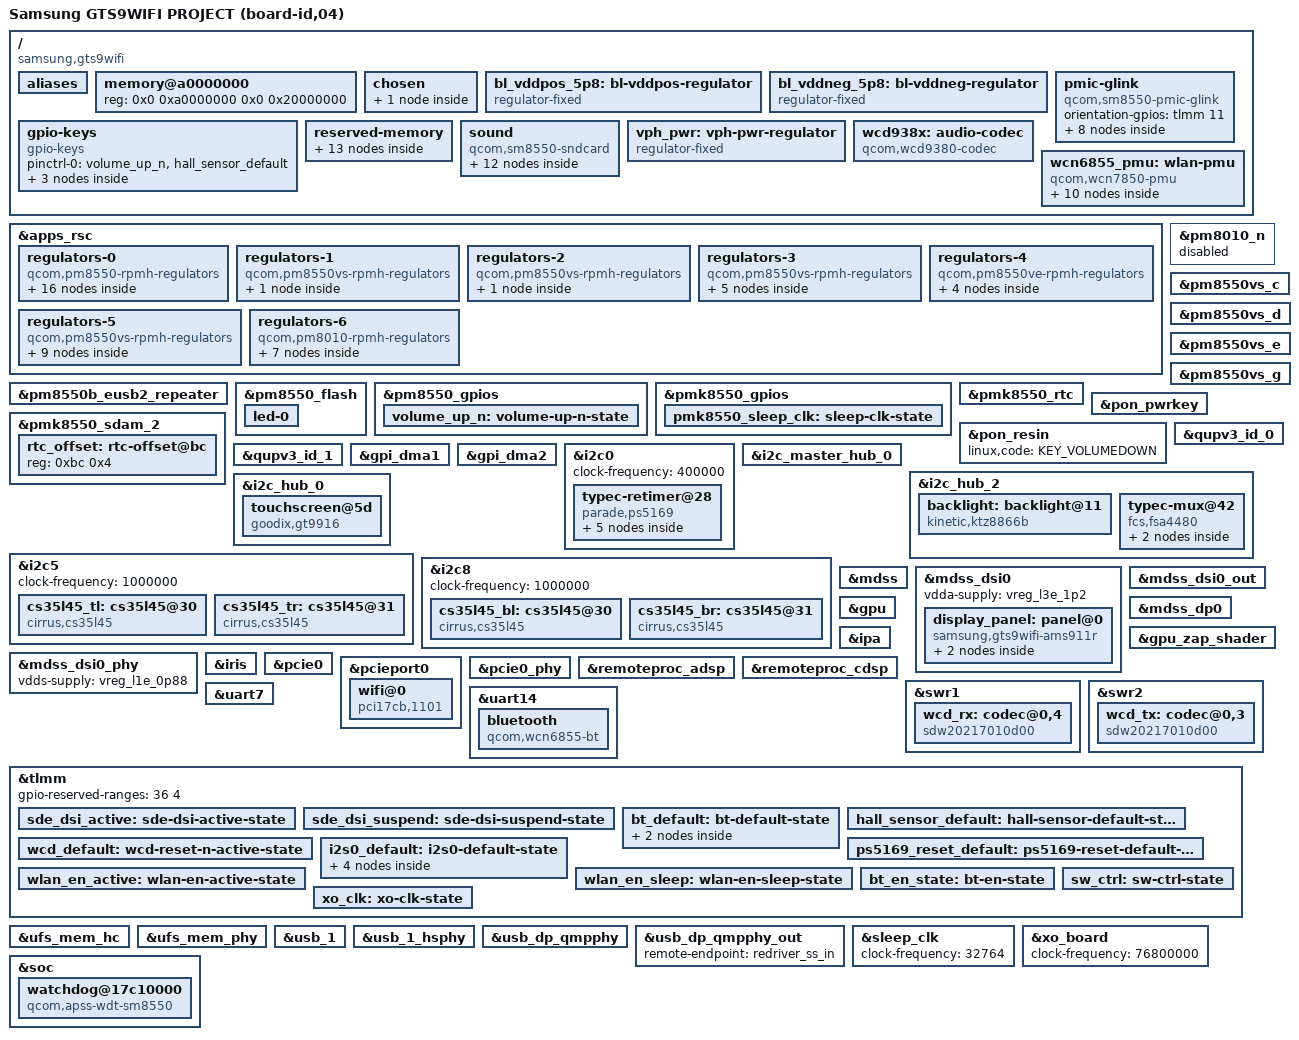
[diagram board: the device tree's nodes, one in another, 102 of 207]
// SPDX-License-Identifier: BSD-3-Clause
/*
 * Copyright (c) 2026, Azkali Manad <a.ffcc7@gmail.com>
 *
 * Device tree for Samsung Galaxy Tab S9 Wi-Fi (SM-X710)
 * Codename: gts9wifi — Qualcomm SM8550 (Snapdragon 8 Gen 2)
 *
 */

/dts-v1/;

#include <dt-bindings/arm/qcom,ids.h>
#include <dt-bindings/leds/common.h>
#include <dt-bindings/pinctrl/qcom,pmic-gpio.h>
#include <dt-bindings/regulator/qcom,rpmh-regulator.h>
#include "sm8550.dtsi"
#include "pm8010.dtsi"
#include "pm8550.dtsi"
#include "pm8550b.dtsi"
/* PMK8550VE shares SID 5 — must precede pm8550ve.dtsi */
#define PMK8550VE_SID 5
#include "pm8550ve.dtsi"
#include "pm8550vs.dtsi"
#include "pmk8550.dtsi"

/delete-node/ &xbl_dt_log_merged_mem;
/delete-node/ &hwfence_shbuf;
/delete-node/ &hyp_tags_reserved_mem;
/delete-node/ &cdsp_secure_heap_mem;
/delete-node/ &trust_ui_vm_mem;
/delete-node/ &trust_ui_vm_dump;
/delete-node/ &trust_ui_vm_qrtr;
/delete-node/ &trust_ui_vm_vblk0_ring;
/delete-node/ &trust_ui_vm_vblk1_ring;
/delete-node/ &trust_ui_vm_swiotlb;
/delete-node/ &oem_vm_vblk0_ring;
/delete-node/ &oem_vm_swiotlb;
/delete-node/ &oem_vm_mem;
/delete-node/ &hyp_ext_tags_mem;
/delete-node/ &hyp_ext_reserved_mem;
/delete-node/ &mpss_dsm_mem;
/delete-node/ &mpss_mem;
/delete-node/ &q6_mpss_dtb_mem;
/delete-node/ &remoteproc_mpss;
/delete-node/ &adspslpi_mem;
/delete-node/ &rmtfs_mem;

/ {
	model = "Samsung GTS9WIFI PROJECT (board-id,04)";
	compatible = "samsung,gts9wifi", "qcom,sm8550", "qcom,kalama-mtp", "qcom,kalama", "qcom,mtp";
	chassis-type = "tablet";
        qcom,msm-id = <0x218 0x20000 0x207 0x20000 0x207 0x10000 0x218 0x10000>;
	qcom,board-id = <0x10008 0x04>;
        dtbo-hw_rev = <0x04>;
        dtbo-hw_rev_end = <0x20>;


	aliases {
		serial0 = &uart7;   /* debug UART (QUP SE7)  */
		serial1 = &uart14;  /* Bluetooth (QUP SE14)  */
	};

	/*
	 * Embedded-DTB path: ABL doesn't patch our blob, so describe a
	 * conservative 512 MiB slice of DRAM at 0xa0000000–0xc0000000.
	 * /proc/iomem on stock confirms System RAM here (excluding splash
	 * region 0xb8000000–0xbab00000 which we mark no-map).
	 */
	memory@a0000000 {
		device_type = "memory";
		reg = <0x0 0xa0000000 0x0 0x20000000>;
	};

	chosen {
		#address-cells = <2>;
		#size-cells = <2>;
		ranges;

		stdout-path = "serial0:115200n8";
		bootargs = "earlycon=qcom_geni,0xa9c000,115200 console=ttyMSM0,115200 loglevel=8 clk_ignore_unused pd_ignore_unused udmabuf.size_limit_mb=256";

		framebuffer: framebuffer@b8000000 {
			compatible = "simple-framebuffer";
			reg = <0x0 0xb8000000 0x0 (1600 * 2560 * 4)>;
			width = <1600>;
			height = <2560>;
			stride = <(1600 * 4)>;
			format = "a8r8g8b8";
		};
	};

	bl_vddpos_5p8: bl-vddpos-regulator {
		compatible = "regulator-fixed";
		regulator-name = "bl_vddpos_5p8";
		regulator-min-microvolt = <5800000>;
		regulator-max-microvolt = <5800000>;
		regulator-enable-ramp-delay = <233>;
		gpio = <&tlmm 30 GPIO_ACTIVE_HIGH>;
		enable-active-high;
	};

	bl_vddneg_5p8: bl-vddneg-regulator {
		compatible = "regulator-fixed";
		regulator-name = "bl_vddneg_5p8";
		regulator-min-microvolt = <5800000>;
		regulator-max-microvolt = <5800000>;
		regulator-enable-ramp-delay = <233>;
		gpio = <&tlmm 31 GPIO_ACTIVE_HIGH>;
		enable-active-high;
	};

	gpio-keys {
		compatible = "gpio-keys";
		pinctrl-0 = <&volume_up_n>, <&hall_sensor_default>;
		pinctrl-names = "default";

		key-volume-up {
			label = "Volume Up";
			linux,code = <KEY_VOLUMEUP>;
			gpios = <&pm8550_gpios 6 GPIO_ACTIVE_LOW>;
			debounce-interval = <15>;
			linux,can-disable;
			wakeup-source;
		};

		event-hall-sensor {
			label = "Hall Effect Sensor";
			gpios = <&tlmm 107 GPIO_ACTIVE_LOW>;
			linux,input-type = <EV_SW>;
			linux,code = <SW_LID>;
			debounce-interval = <15>;
			linux,can-disable;
			wakeup-source;
		};

		event-hall-wacom {
			label = "Hall Effect Sensor (Wacom S-Pen)";
			gpios = <&tlmm 203 GPIO_ACTIVE_LOW>;
			linux,input-type = <EV_SW>;
			linux,code = <SW_TABLET_MODE>;
			debounce-interval = <15>;
			linux,can-disable;
		};
	};

	pmic-glink {
		compatible = "qcom,sm8550-pmic-glink", "qcom,pmic-glink";
		#address-cells = <1>;
		#size-cells = <0>;
		orientation-gpios = <&tlmm 11 GPIO_ACTIVE_HIGH>;

		connector@0 {
			compatible = "usb-c-connector";
			reg = <0>;
			power-role = "dual";
			data-role = "dual";

			ports {
				#address-cells = <1>;
				#size-cells = <0>;

				port@0 {
					reg = <0>;
					pmic_glink_hs_in: endpoint {
						remote-endpoint = <&usb_1_dwc3_hs>;
					};
				};
				port@1 {
					reg = <1>;
					pmic_glink_ss_in: endpoint {
						remote-endpoint = <&redriver_ss_out>;
					};
				};
				port@2 {
					reg = <2>;
					pmic_glink_sbu: endpoint {
						remote-endpoint = <&fsa4480_sbu_mux>;
					};
				};
			};
		};
	};

	/*
	 * Reserved-memory carveouts derived from the stock gts9wifi
	 * bootloader (BL_X710XXU5CYD9 — xbl_config.elf "Kailua" memory
	 * map). Only regions the hardware still reads during the
	 * UEFI→Linux hand-off are kept no-map; ranges freed by
	 * ExitBootServices (DXE heap, UEFI FD) or migrated out by
	 * uniLoader stripping the Qualcomm hypervisor (trust_ui_vm,
	 * oem_vm, hyp_ext, RSRV3) are left available to Linux.
	 */
	reserved-memory {
		xbl_ramdump_mem: xbl-ramdump-region@81200000 {
			reg = <0 0x81200000 0 0x280000>;
			no-map;
		};

		xbl_dt_log_mem: xbl-dt-log-region@81a00000 {
			reg = <0 0x81a00000 0 0x40000>;
			no-map;
		};

		aop_image_mem: aop-image-region@81c00000 {
			reg = <0 0x81c00000 0 0x60000>;
			no-map;
		};

		adspslpi_mem: adspslpi-region@9ea00000 {
			reg = <0 0x9ea00000 0 0x4080000>;
			no-map;
		};

		/*
		 * Samsung downstream DPU programs a demura calibration LUT
		 * here at boot and the display controller keeps scanning it
		 * until the mainline msm DRM driver reinitialises the
		 * pipeline. Reserve it so simple-framebuffer hand-off can't
		 * clobber an in-flight DPU read.
		 */
		display_demura_mem: display-demura-region@a2a80000 {
			reg = <0x0 0xa2a80000 0x0 0x2b00000>;
			no-map;
		};

		/* XBL "RSRV2" — purpose undocumented, reserved out of caution. */
		rsrv2_mem: rsrv2-region@a5580000 {
			reg = <0x0 0xa5580000 0x0 0xb80000>;
			no-map;
		};

		/*
		 * XBL "DBI Dump" — debug boot-info dump target, mapped as
		 * MMAP_IO in the bootloader memory map but still falls
		 * inside the DDR window Linux enumerates.
		 */
		dbi_dump_mem: dbi-dump-region@a6100000 {
			reg = <0x0 0xa6100000 0x0 0xf00000>;
			no-map;
		};

		/*
		 * Bootloader's "Display Reserved" is 43 MiB, covering the
		 * 1600x2560x4 framebuffer plus Samsung secondary / cursor
		 * planes. simple-framebuffer only uses the first ~16 MiB
		 * but the whole region must stay no-map until takeover.
		 */
		cont_splash_mem: splash-region@b8000000 {
			reg = <0x0 0xb8000000 0x0 0x2b00000>;
			no-map;
		};

		rmtfs_mem: rmtfs-region@ccd00000 {
			compatible = "qcom,rmtfs-mem";
			reg = <0x0 0xccd00000 0x0 0x280000>;
			no-map;
			qcom,client-id = <1>;
		};

		hwfence_shbuf: hwfence-shbuf-region@e6440000 {
			reg = <0 0xe6440000 0 0x2dd000>;
			no-map;
		};

		ramoops@f0000000 {
			compatible = "ramoops";
			reg = <0x0 0xf0000000 0x0 0x200000>;
			record-size  = <0x40000>;	/* 256 KiB per oops record  */
			console-size = <0x80000>;	/* 512 KiB kernel console   */
			pmsg-size    = <0x40000>;	/* 256 KiB userspace pmsg   */
			/* remaining ~768 KiB is padding / alignment slack   */
			mem-type = <0>;
			no-map;
		};

		/* XBL "NOMAP" carveout at top of low bank, 8 MiB. */
		llcc_lpi_mem: llcc-lpi-region@ff800000 {
			reg = <0 0xff800000 0 0x800000>;
			no-map;
		};

		linux,cma {
			compatible = "shared-dma-pool";
			size = <0x0 0x20000000>;	/* 512 MiB */
			reusable;
			linux,cma-default;
		};
	};

	sound {
		compatible = "qcom,sm8550-sndcard", "qcom,sm8450-sndcard";
		model = "Samsung-GTS9WiFi";
		pinctrl-names = "default";
		pinctrl-0 = <&i2s0_default>;

		audio-routing =
			"IN1_HPHL",      "HPHL_OUT",
			"IN2_HPHR",      "HPHR_OUT",
			"AMIC1",         "MIC BIAS1",
			"AMIC2",         "MIC BIAS2",
			"AMIC3",         "MIC BIAS3",
			"AMIC4",         "MIC BIAS3",
			"TX SWR_INPUT0", "ADC1_OUTPUT",
			"TX SWR_INPUT1", "ADC2_OUTPUT",
			"TX SWR_INPUT0", "ADC3_OUTPUT",
			"TX SWR_INPUT1", "ADC4_OUTPUT";

		speaker-dai-link {
			link-name = "CS35L41 Speaker Playback";
			cpu    { sound-dai = <&q6apmbedai SECONDARY_MI2S_RX>; };
			codec  { sound-dai = <&cs35l45_tl>, <&cs35l45_tr>,
					     <&cs35l45_bl>, <&cs35l45_br>; };
			platform { sound-dai = <&q6apm>; };
		};

		wcd-playback-dai-link {
			link-name = "WCD Playback";
			cpu    { sound-dai = <&q6apmbedai RX_CODEC_DMA_RX_0>; };
			codec  { sound-dai = <&wcd938x 0>, <&swr1 0>, <&lpass_rxmacro 0>; };
			platform { sound-dai = <&q6apm>; };
		};

		wcd-capture-dai-link {
			link-name = "WCD Capture";
			cpu    { sound-dai = <&q6apmbedai TX_CODEC_DMA_TX_3>; };
			codec  { sound-dai = <&wcd938x 1>, <&swr2 0>, <&lpass_txmacro 0>; };
			platform { sound-dai = <&q6apm>; };
		};
	};

	vph_pwr: vph-pwr-regulator {
		compatible = "regulator-fixed";
		regulator-name = "vph_pwr";
		regulator-min-microvolt = <3700000>;
		regulator-max-microvolt = <3700000>;
		regulator-always-on;
		regulator-boot-on;
	};

	wcd938x: audio-codec {
		compatible = "qcom,wcd9380-codec";
		pinctrl-names = "default";
		pinctrl-0 = <&wcd_default>;

		qcom,micbias1-microvolt = <2750000>;
		qcom,micbias2-microvolt = <2750000>;
		qcom,micbias3-microvolt = <2750000>;
		qcom,micbias4-microvolt = <2750000>;
		qcom,mbhc-buttons-vthreshold-microvolt =
			<75000 150000 237000 500000
			 500000 500000 500000 500000>;
		qcom,mbhc-headset-vthreshold-microvolt = <1700000>;
		qcom,mbhc-headphone-vthreshold-microvolt = <50000>;
		qcom,rx-device = <&wcd_rx>;
		qcom,tx-device = <&wcd_tx>;

		reset-gpios = <&tlmm 108 GPIO_ACTIVE_LOW>;

		vdd-buck-supply     = <&vreg_l15b_1p8>;
		vdd-rxtx-supply     = <&vreg_l15b_1p8>;
		vdd-io-supply       = <&vreg_l15b_1p8>;
		vdd-mic-bias-supply = <&vreg_bob1>;

		#sound-dai-cells = <1>;
	};

	wcn6855_pmu: wlan-pmu {
		compatible = "qcom,wcn7850-pmu";

		pinctrl-names = "default", "sleep";
		pinctrl-0 = <&wlan_en_active>, <&bt_en_state>, <&xo_clk>;
		pinctrl-1 = <&wlan_en_sleep>;

		wlan-enable-gpios = <&tlmm 80 GPIO_ACTIVE_HIGH>;
		bt-enable-gpios   = <&tlmm 81 GPIO_ACTIVE_HIGH>;
		swctrl-gpios      = <&tlmm 82 GPIO_ACTIVE_HIGH>;
		xo-clk-gpios      = <&tlmm 204 GPIO_ACTIVE_HIGH>;

		vdd-supply        = <&vreg_s2g_0p8>;
		vddio-supply      = <&vreg_l15b_1p8>;
		vddaon-supply     = <&vreg_s2g_0p8>;
		vdddig-supply     = <&vreg_s4e_0p9>;
		vddrfa1p2-supply  = <&vreg_s4g_1p3>;
		vddrfa1p8-supply  = <&vreg_s6g_1p8>;
		vddpcie1p3-supply = <&vreg_s4g_1p3>;
		vddpcie1p9-supply = <&vreg_s6g_1p8>;
		vddpmu-supply     = <&vreg_s2g_0p8>;
		vddpmumx-supply   = <&vreg_s2g_0p8>;
		vddpmucx-supply   = <&vreg_s4e_0p9>;

		regulators {
			vreg_pmu_rfa_cmn:  ldo0 { regulator-name = "vreg_pmu_rfa_cmn"; };
			vreg_pmu_aon_0p59: ldo1 { regulator-name = "vreg_pmu_aon_0p59"; };
			vreg_pmu_wlcx_0p8: ldo2 { regulator-name = "vreg_pmu_wlcx_0p8"; };
			vreg_pmu_wlmx_0p85: ldo3 { regulator-name = "vreg_pmu_wlmx_0p85"; };
			vreg_pmu_rfa_0p8:  ldo5 { regulator-name = "vreg_pmu_rfa_0p8"; };
			vreg_pmu_rfa_1p2:  ldo6 { regulator-name = "vreg_pmu_rfa_1p2"; };
			vreg_pmu_rfa_1p8:  ldo7 { regulator-name = "vreg_pmu_rfa_1p8"; };
			vreg_pmu_pcie_0p9: ldo8 { regulator-name = "vreg_pmu_pcie_0p9"; };
			vreg_pmu_pcie_1p8: ldo9 { regulator-name = "vreg_pmu_pcie_1p8"; };
		};
	};
};

&apps_rsc {
	regulators-0 {
		compatible = "qcom,pm8550-rpmh-regulators";
		qcom,pmic-id = "b";

		vdd-bob1-supply       = <&vph_pwr>;
		vdd-bob2-supply       = <&vph_pwr>;
		vdd-l1-l4-l10-supply  = <&vreg_s6g_1p8>;
		vdd-l2-l13-l14-supply = <&vreg_bob1>;
		vdd-l3-supply         = <&vreg_s4g_1p3>;
		vdd-l5-l16-supply     = <&vreg_bob1>;
		vdd-l6-l7-supply      = <&vreg_bob1>;
		vdd-l8-l9-supply      = <&vreg_bob1>;
		vdd-l11-supply        = <&vreg_s4g_1p3>;
		vdd-l12-supply        = <&vreg_s6g_1p8>;
		vdd-l15-supply        = <&vreg_s6g_1p8>;
		vdd-l17-supply        = <&vreg_bob2>;

		vreg_bob1: bob1 {
			regulator-name = "vreg_bob1";
			regulator-min-microvolt = <3296000>;
			regulator-max-microvolt = <3960000>;
			regulator-initial-mode = <RPMH_REGULATOR_MODE_HPM>;
		};

		vreg_bob2: bob2 {
			regulator-name = "vreg_bob2";
			regulator-min-microvolt = <2720000>;
			regulator-max-microvolt = <3960000>;
			regulator-initial-mode = <RPMH_REGULATOR_MODE_HPM>;
		};

		vreg_l1b_1p8: ldo1 {
			regulator-name = "vreg_l1b_1p8";
			regulator-min-microvolt = <1800000>;
			regulator-max-microvolt = <1800000>;
			regulator-initial-mode = <RPMH_REGULATOR_MODE_HPM>;
		};

		vreg_l2b_3p0: ldo2 {
			regulator-name = "vreg_l2b_3p0";
			regulator-min-microvolt = <3008000>;
			regulator-max-microvolt = <3008000>;
			regulator-initial-mode = <RPMH_REGULATOR_MODE_HPM>;
		};

		vreg_l5b_3p1: ldo5 {
			regulator-name = "vreg_l5b_3p1";
			regulator-min-microvolt = <3104000>;
			regulator-max-microvolt = <3104000>;
			regulator-initial-mode = <RPMH_REGULATOR_MODE_HPM>;
		};

		vreg_l6b_1p8: ldo6 {
			regulator-name = "vreg_l6b_1p8";
			regulator-min-microvolt = <1800000>;
			regulator-max-microvolt = <3008000>;
			regulator-initial-mode = <RPMH_REGULATOR_MODE_HPM>;
		};

		vreg_l7b_1p8: ldo7 {
			regulator-name = "vreg_l7b_1p8";
			regulator-min-microvolt = <1800000>;
			regulator-max-microvolt = <3008000>;
			regulator-initial-mode = <RPMH_REGULATOR_MODE_HPM>;
		};

		vreg_l8b_1p8: ldo8 {
			regulator-name = "vreg_l8b_1p8";
			regulator-min-microvolt = <1800000>;
			regulator-max-microvolt = <3008000>;
			regulator-initial-mode = <RPMH_REGULATOR_MODE_HPM>;
		};

		vreg_l9b_2p9: ldo9 {
			regulator-name = "vreg_l9b_2p9";
			regulator-min-microvolt = <2960000>;
			regulator-max-microvolt = <3008000>;
			regulator-initial-mode = <RPMH_REGULATOR_MODE_HPM>;
		};

		vreg_l11b_1p2: ldo11 {
			regulator-name = "vreg_l11b_1p2";
			regulator-min-microvolt = <1200000>;
			regulator-max-microvolt = <1504000>;
			regulator-initial-mode = <RPMH_REGULATOR_MODE_HPM>;
		};

		vreg_l12b_1p8: ldo12 {
			regulator-name = "vreg_l12b_1p8";
			regulator-min-microvolt = <1800000>;
			regulator-max-microvolt = <1800000>;
			regulator-initial-mode = <RPMH_REGULATOR_MODE_HPM>;
		};

		vreg_l13b_3p0: ldo13 {
			regulator-name = "vreg_l13b_3p0";
			regulator-min-microvolt = <3000000>;
			regulator-max-microvolt = <3000000>;
			regulator-initial-mode = <RPMH_REGULATOR_MODE_HPM>;
		};

		vreg_l14b_3p2: ldo14 {
			regulator-name = "vreg_l14b_3p2";
			regulator-min-microvolt = <3200000>;
			regulator-max-microvolt = <3200000>;
			regulator-initial-mode = <RPMH_REGULATOR_MODE_HPM>;
		};

		vreg_l15b_1p8: ldo15 {
			regulator-name = "vreg_l15b_1p8";
			regulator-min-microvolt = <1800000>;
			regulator-max-microvolt = <1800000>;
			regulator-initial-mode = <RPMH_REGULATOR_MODE_HPM>;
			regulator-allow-set-load;
			regulator-allowed-modes =
				<RPMH_REGULATOR_MODE_LPM
				 RPMH_REGULATOR_MODE_HPM>;
			regulator-always-on;
		};

		vreg_l16b_2p8: ldo16 {
			regulator-name = "vreg_l16b_2p8";
			regulator-min-microvolt = <2800000>;
			regulator-max-microvolt = <2800000>;
			regulator-initial-mode = <RPMH_REGULATOR_MODE_HPM>;
		};

		vreg_l17b_2p5: ldo17 {
			regulator-name = "vreg_l17b_2p5";
			regulator-min-microvolt = <2504000>;
			regulator-max-microvolt = <2504000>;
			regulator-initial-mode = <RPMH_REGULATOR_MODE_HPM>;
		};
	};

	regulators-1 {
		compatible = "qcom,pm8550vs-rpmh-regulators";
		qcom,pmic-id = "c";
		vdd-l3-supply = <&vreg_s4e_0p9>;

		vreg_l3c_0p91: ldo3 {
			regulator-name = "vreg_l3c_0p9";
			regulator-min-microvolt = <880000>;
			regulator-max-microvolt = <912000>;
			regulator-initial-mode = <RPMH_REGULATOR_MODE_HPM>;
		};
	};

	regulators-2 {
		compatible = "qcom,pm8550vs-rpmh-regulators";
		qcom,pmic-id = "d";
		vdd-l1-supply = <&vreg_s4e_0p9>;

		vreg_l1d_0p88: ldo1 {
			regulator-name = "vreg_l1d_0p88";
			regulator-min-microvolt = <880000>;
			regulator-max-microvolt = <920000>;
			regulator-initial-mode = <RPMH_REGULATOR_MODE_HPM>;
		};
	};

	regulators-3 {
		compatible = "qcom,pm8550vs-rpmh-regulators";
		qcom,pmic-id = "e";
		vdd-l1-supply = <&vreg_s4e_0p9>;
		vdd-l2-supply = <&vreg_s4e_0p9>;
		vdd-l3-supply = <&vreg_s4g_1p3>;
		vdd-s4-supply = <&vph_pwr>;
		vdd-s5-supply = <&vph_pwr>;

		vreg_s4e_0p9: smps4 {
			regulator-name = "vreg_s4e_0p9";
			regulator-min-microvolt = <904000>;
			regulator-max-microvolt = <984000>;
			regulator-initial-mode = <RPMH_REGULATOR_MODE_HPM>;
		};

		vreg_s5e_1p1: smps5 {
			regulator-name = "vreg_s5e_1p1";
			regulator-min-microvolt = <1080000>;
			regulator-max-microvolt = <1120000>;
			regulator-initial-mode = <RPMH_REGULATOR_MODE_HPM>;
		};

		vreg_l1e_0p88: ldo1 {
			regulator-name = "vreg_l1e_0p88";
			regulator-min-microvolt = <880000>;
			regulator-max-microvolt = <880000>;
			regulator-initial-mode = <RPMH_REGULATOR_MODE_HPM>;
		};

		vreg_l2e_0p9: ldo2 {
			regulator-name = "vreg_l2e_0p9";
			regulator-min-microvolt = <904000>;
			regulator-max-microvolt = <970000>;
			regulator-initial-mode = <RPMH_REGULATOR_MODE_HPM>;
		};

		vreg_l3e_1p2: ldo3 {
			regulator-name = "vreg_l3e_1p2";
			regulator-min-microvolt = <1200000>;
			regulator-max-microvolt = <1200000>;
			regulator-initial-mode = <RPMH_REGULATOR_MODE_HPM>;
		};
	};

	regulators-4 {
		compatible = "qcom,pm8550ve-rpmh-regulators";
		qcom,pmic-id = "f";
		vdd-l1-supply = <&vreg_s4e_0p9>;
		vdd-l2-supply = <&vreg_s4e_0p9>;
		vdd-l3-supply = <&vreg_s4e_0p9>;
		vdd-s4-supply = <&vph_pwr>;

		vreg_s4f_0p5: smps4 {
			regulator-name = "vreg_s4f_0p5";
			regulator-min-microvolt = <500000>;
			regulator-max-microvolt = <700000>;
			regulator-initial-mode = <RPMH_REGULATOR_MODE_HPM>;
		};

		vreg_l1f_0p9: ldo1 {
			regulator-name = "vreg_l1f_0p9";
			regulator-min-microvolt = <912000>;
			regulator-max-microvolt = <912000>;
			regulator-initial-mode = <RPMH_REGULATOR_MODE_HPM>;
		};

		vreg_l2f_0p88: ldo2 {
			regulator-name = "vreg_l2f_0p88";
			regulator-min-microvolt = <880000>;
			regulator-max-microvolt = <912000>;
			regulator-initial-mode = <RPMH_REGULATOR_MODE_HPM>;
		};

		vreg_l3f_0p91: ldo3 {
			regulator-name = "vreg_l3f_0p91";
			regulator-min-microvolt = <880000>;
			regulator-max-microvolt = <912000>;
			regulator-initial-mode = <RPMH_REGULATOR_MODE_HPM>;
		};
	};

	regulators-5 {
		compatible = "qcom,pm8550vs-rpmh-regulators";
		qcom,pmic-id = "g";
		vdd-l1-supply = <&vreg_s4g_1p3>;
		vdd-l2-supply = <&vreg_s4g_1p3>;
		vdd-l3-supply = <&vreg_s4g_1p3>;
		vdd-s1-supply = <&vph_pwr>;
		vdd-s2-supply = <&vph_pwr>;
		vdd-s3-supply = <&vph_pwr>;
		vdd-s4-supply = <&vph_pwr>;
		vdd-s5-supply = <&vph_pwr>;
		vdd-s6-supply = <&vph_pwr>;

		vreg_s1g_1p2: smps1 {
			regulator-name = "vreg_s1g_1p2";
			regulator-min-microvolt = <1200000>;
			regulator-max-microvolt = <1300000>;
			regulator-initial-mode = <RPMH_REGULATOR_MODE_HPM>;
		};

		vreg_s2g_0p8: smps2 {
			regulator-name = "vreg_s2g_0p8";
			regulator-min-microvolt = <800000>;
			regulator-max-microvolt = <1000000>;
			regulator-initial-mode = <RPMH_REGULATOR_MODE_HPM>;
		};

		vreg_s3g_0p7: smps3 {
			regulator-name = "vreg_s3g_0p7";
			regulator-min-microvolt = <600000>;
			regulator-max-microvolt = <1900000>;
			regulator-initial-mode = <RPMH_REGULATOR_MODE_HPM>;
		};

		vreg_s4g_1p3: smps4 {
			regulator-name = "vreg_s4g_1p3";
			regulator-min-microvolt = <1256000>;
			regulator-max-microvolt = <1408000>;
			regulator-initial-mode = <RPMH_REGULATOR_MODE_HPM>;
		};

		vreg_s5g_0p8: smps5 {
			regulator-name = "vreg_s5g_0p8";
			regulator-min-microvolt = <500000>;
			regulator-max-microvolt = <1004000>;
			regulator-initial-mode = <RPMH_REGULATOR_MODE_HPM>;
		};

		vreg_s6g_1p8: smps6 {
			regulator-name = "vreg_s6g_1p8";
			regulator-min-microvolt = <1800000>;
			regulator-max-microvolt = <2000000>;
			regulator-initial-mode = <RPMH_REGULATOR_MODE_HPM>;
		};

		vreg_l1g_1p2: ldo1 {
			regulator-name = "vreg_l1g_1p2";
			regulator-min-microvolt = <1200000>;
			regulator-max-microvolt = <1200000>;
			regulator-initial-mode = <RPMH_REGULATOR_MODE_HPM>;
		};

		vreg_l2g_1p2: ldo2 {
			regulator-name = "vreg_l2g_1p2";
			regulator-min-microvolt = <1200000>;
			regulator-max-microvolt = <1200000>;
			regulator-initial-mode = <RPMH_REGULATOR_MODE_HPM>;
		};

		vreg_l3g_1p2: ldo3 {
			regulator-name = "vreg_l3g_1p2";
			regulator-min-microvolt = <1200000>;
			regulator-max-microvolt = <1200000>;
			regulator-initial-mode = <RPMH_REGULATOR_MODE_HPM>;
		};
	};

	regulators-6 {
		compatible = "qcom,pm8010-rpmh-regulators";
		qcom,pmic-id = "m";
		vdd-l1-l2-supply = <&vreg_s4g_1p3>;
		vdd-l3-l4-supply = <&vreg_bob2>;
		vdd-l5-supply    = <&vreg_s6g_1p8>;
		vdd-l6-supply    = <&vreg_bob2>;
		vdd-l7-supply    = <&vreg_bob2>;

		vreg_l1m_1p056: ldo1 {
			regulator-name = "vreg_l1m_1p056";
			regulator-min-microvolt = <1056000>;
			regulator-max-microvolt = <1056000>;
			regulator-initial-mode = <RPMH_REGULATOR_MODE_HPM>;
		};

		vreg_l2m_1p056: ldo2 {
			regulator-name = "vreg_l2m_1p056";
			regulator-min-microvolt = <1056000>;
			regulator-max-microvolt = <1056000>;
			regulator-initial-mode = <RPMH_REGULATOR_MODE_HPM>;
		};

		vreg_l3m_2p8: ldo3 {
			regulator-name = "vreg_l3m_2p8";
			regulator-min-microvolt = <2800000>;
			regulator-max-microvolt = <2800000>;
			regulator-initial-mode = <RPMH_REGULATOR_MODE_HPM>;
		};

		vreg_l4m_2p8: ldo4 {
			regulator-name = "vreg_l4m_2p8";
			regulator-min-microvolt = <2800000>;
			regulator-max-microvolt = <2800000>;
			regulator-initial-mode = <RPMH_REGULATOR_MODE_HPM>;
		};

		vreg_l5m_1p8: ldo5 {
			regulator-name = "vreg_l5m_1p8";
			regulator-min-microvolt = <1800000>;
			regulator-max-microvolt = <1800000>;
			regulator-initial-mode = <RPMH_REGULATOR_MODE_HPM>;
		};

		vreg_l6m_1p8: ldo6 {
			regulator-name = "vreg_l6m_1p8";
			regulator-min-microvolt = <1800000>;
			regulator-max-microvolt = <1800000>;
			regulator-initial-mode = <RPMH_REGULATOR_MODE_HPM>;
		};

		vreg_l7m_2p9: ldo7 {
			regulator-name = "vreg_l7m_2p9";
			regulator-min-microvolt = <2800000>;
			regulator-max-microvolt = <2904000>;
			regulator-initial-mode = <RPMH_REGULATOR_MODE_HPM>;
		};
	};
};

&pm8010_n { status = "disabled"; };

&pm8550b_eusb2_repeater {
	vdd18-supply = <&vreg_l15b_1p8>;
	vdd3-supply  = <&vreg_l5b_3p1>;
};

&pm8550_flash {
	status = "okay";
	led-0 {
		function = LED_FUNCTION_FLASH;
		color = <LED_COLOR_ID_WHITE>;
		led-sources = <1>;
		led-max-microamp = <400000>;
		flash-max-microamp = <400000>;
		flash-max-timeout-us = <300000>;
		function-enumerator = <0>;
	};
};

&pm8550_gpios {
	volume_up_n: volume-up-n-state {
		pins = "gpio6";
		function = "normal";
		power-source = <1>;
		bias-pull-up;
		input-enable;
	};
};

&pm8550vs_c { status = "okay"; };
&pm8550vs_d { status = "okay"; };
&pm8550vs_e { status = "okay"; };
&pm8550vs_g { status = "okay"; };

&pmk8550_gpios {
	pmk8550_sleep_clk: sleep-clk-state {
		pins = "gpio3";
		function = "func1";
		input-disable;
		output-enable;
		bias-disable;
		power-source = <0>;
	};
};

&pmk8550_rtc {
	nvmem-cells = <&rtc_offset>;
	nvmem-cell-names = "offset";
};

&pmk8550_sdam_2 {
	rtc_offset: rtc-offset@bc {
		reg = <0xbc 0x4>;
	};
};

&pon_pwrkey { status = "okay"; };
&pon_resin  { status = "okay"; linux,code = <KEY_VOLUMEDOWN>; };

&qupv3_id_0 { status = "okay"; };
&qupv3_id_1 { status = "okay"; };

&gpi_dma1 { status = "okay"; };
&gpi_dma2 { status = "okay"; };

&i2c0 {
	clock-frequency = <400000>;
	status = "okay";

	typec-retimer@28 {
		compatible = "parade,ps5169";
		reg = <0x28>;
		pinctrl-names = "default";
		pinctrl-0 = <&ps5169_reset_default>;
		reset-gpios = <&tlmm 7 GPIO_ACTIVE_LOW>;
		orientation-switch;
		retimer-switch;

		ports {
			#address-cells = <1>;
			#size-cells = <0>;
			port@0 {
				reg = <0>;
				redriver_ss_out: endpoint {
					remote-endpoint = <&pmic_glink_ss_in>;
				};
			};
			port@1 {
				reg = <1>;
				redriver_ss_in: endpoint {
					data-lanes = <3 2 1 0>;
					remote-endpoint = <&usb_dp_qmpphy_out>;
				};
			};
		};
	};
};

&i2c_master_hub_0 { status = "okay"; };

&i2c_hub_2 {
	status = "okay";

	backlight: backlight@11 {
		compatible = "kinetic,ktz8866b";
		reg = <0x11>;
		vddpos-supply = <&bl_vddpos_5p8>;
		vddneg-supply = <&bl_vddneg_5p8>;
		enable-gpios = <&tlmm 128 GPIO_ACTIVE_HIGH>;
		current-num-sinks = <5>;
		kinetic,current-ramp-delay-ms = <256>;
		kinetic,led-enable-ramp-delay-ms = <8>;
		kinetic,enable-lcd-bias;
	};

	typec-mux@42 {
		compatible = "fcs,fsa4480";
		reg = <0x42>;
		vcc-supply = <&vreg_bob1>;
		mode-switch;
		orientation-switch;
		port {
			fsa4480_sbu_mux: endpoint {
				remote-endpoint = <&pmic_glink_sbu>;
			};
		};
	};
};

&i2c_hub_0 {
	status = "okay";

	touchscreen@5d {
		compatible = "goodix,gt9916";
		reg = <0x5d>;

		interrupt-parent = <&tlmm>;
		interrupts = <25 IRQ_TYPE_EDGE_FALLING>;

		reset-gpios = <&tlmm 24 GPIO_ACTIVE_HIGH>;

		touchscreen-size-x = <1600>;
		touchscreen-size-y = <2560>;

		avdd-supply  = <&vreg_l2b_3p0>;
		vddio-supply = <&vreg_l12b_1p8>;
	};
};

&i2c5 {
	clock-frequency = <1000000>;
	status = "okay";

	cs35l45_tl: cs35l45@30 {
		compatible = "cirrus,cs35l45";
		reg = <0x30>;
		interrupt-parent = <&tlmm>;
		interrupts = <98 IRQ_TYPE_LEVEL_LOW>;
		reset-gpios = <&tlmm 90 GPIO_ACTIVE_HIGH>;
		#sound-dai-cells = <1>;
		sound-name-prefix = "TL";
	};

	cs35l45_tr: cs35l45@31 {
		compatible = "cirrus,cs35l45";
		reg = <0x31>;
		interrupt-parent = <&tlmm>;
		interrupts = <99 IRQ_TYPE_LEVEL_LOW>;
		reset-gpios = <&tlmm 90 GPIO_ACTIVE_HIGH>;
		#sound-dai-cells = <1>;
		sound-name-prefix = "TR";
	};
};

&i2c8 {
	clock-frequency = <1000000>;
	status = "okay";

	cs35l45_bl: cs35l45@30 {
		compatible = "cirrus,cs35l45";
		reg = <0x30>;
		interrupt-parent = <&tlmm>;
		interrupts = <8 IRQ_TYPE_LEVEL_LOW>;
		reset-gpios = <&tlmm 90 GPIO_ACTIVE_HIGH>;
		#sound-dai-cells = <1>;
		sound-name-prefix = "BL";
	};

	cs35l45_br: cs35l45@31 {
		compatible = "cirrus,cs35l45";
		reg = <0x31>;
		interrupt-parent = <&tlmm>;
		interrupts = <17 IRQ_TYPE_LEVEL_LOW>;
		reset-gpios = <&tlmm 90 GPIO_ACTIVE_HIGH>;
		#sound-dai-cells = <1>;
		sound-name-prefix = "BR";
	};
};

&mdss { status = "okay"; };

&mdss_dsi0 {
	vdda-supply = <&vreg_l3e_1p2>;
	status = "okay";

	/*
	 * TODO: write/upstream panel driver for samsung,ams911r10
	 */
	display_panel: panel@0 {
		compatible = "samsung,gts9wifi-ams911r";
		reg = <0>;
		pinctrl-names = "default", "sleep";
		pinctrl-0 = <&sde_dsi_active>;
		pinctrl-1 = <&sde_dsi_suspend>;
		vddio-supply = <&vreg_s3g_0p7>;
		avdd-supply  = <&bl_vddpos_5p8>;
		avee-supply  = <&bl_vddneg_5p8>;
		reset-gpios  = <&tlmm 125 GPIO_ACTIVE_LOW>;
		backlight    = <&backlight>;
		port {
			panel_in: endpoint {
				remote-endpoint = <&mdss_dsi0_out>;
			};
		};
	};
};

&mdss_dsi0_out {
	remote-endpoint = <&panel_in>;
	data-lanes = <0 1 2 3>;
};

&mdss_dsi0_phy {
	vdds-supply = <&vreg_l1e_0p88>;
	status = "okay";
};

&mdss_dp0 { status = "okay"; };

&gpu { status = "okay"; };

&gpu_zap_shader {
	firmware-name = "qcom/sm8550/gts9wifi/a740_zap.mbn";
};

&ipa {
	qcom,gsi-loader = "self";
	memory-region = <&ipa_fw_mem>;
	firmware-name = "qcom/sm8550/gts9wifi/ipa_fws.mbn";
	status = "okay";
};

&iris {
	firmware-name = "qcom/sm8550/gts9wifi/vpu30_4v.mbn";
	status = "okay";
};

&pcie0 {
	wake-gpios  = <&tlmm 96 GPIO_ACTIVE_HIGH>;
	perst-gpios = <&tlmm 94 GPIO_ACTIVE_LOW>;
	pinctrl-0   = <&pcie0_default_state>;
	pinctrl-names = "default";
	status = "okay";
};

&pcieport0 {
	wifi@0 {
		compatible = "pci17cb,1101";
		reg = <0x10000 0x0 0x0 0x0 0x0>;
		vddrfacmn-supply  = <&vreg_pmu_rfa_cmn>;
		vddaon-supply     = <&vreg_pmu_aon_0p59>;
		vddwlcx-supply    = <&vreg_pmu_wlcx_0p8>;
		vddwlmx-supply    = <&vreg_pmu_wlmx_0p85>;
		vddrfa0p8-supply  = <&vreg_pmu_rfa_0p8>;
		vddrfa1p2-supply  = <&vreg_pmu_rfa_1p2>;
		vddrfa1p7-supply  = <&vreg_s6g_1p8>;
		vddrfa1p8-supply  = <&vreg_s6g_1p8>;
		vddpcie0p9-supply = <&vreg_pmu_pcie_0p9>;
		vddpcie1p8-supply = <&vreg_pmu_pcie_1p8>;
	};
};

&pcie0_phy {
	vdda-phy-supply = <&vreg_l1e_0p88>;
	vdda-pll-supply = <&vreg_l3e_1p2>;
	status = "okay";
};

&remoteproc_adsp {
	firmware-name = "qcom/sm8550/gts9wifi/adsp.mbn",
			"qcom/sm8550/gts9wifi/adsp_dtb.mbn";
	status = "okay";
};

&remoteproc_cdsp {
	firmware-name = "qcom/sm8550/gts9wifi/cdsp.mbn",
			"qcom/sm8550/gts9wifi/cdsp_dtb.mbn";
	status = "okay";
};

&swr1 {
	status = "okay";
	wcd_rx: codec@0,4 {
		compatible = "sdw20217010d00";
		reg = <0 4>;
		qcom,rx-port-mapping = <1 2 3 4 5>;
	};
};

&swr2 {
	status = "okay";
	wcd_tx: codec@0,3 {
		compatible = "sdw20217010d00";
		reg = <0 3>;
		qcom,tx-port-mapping = <2 2 3 4>;
	};
};

&uart7 { status = "okay"; };

&uart14 {
	status = "okay";

	bluetooth {
		compatible = "qcom,wcn6855-bt";

		pinctrl-names = "default";
		pinctrl-0 = <&bt_default>;

		enable-gpios  = <&tlmm 81 GPIO_ACTIVE_HIGH>;
		swctrl-gpios  = <&tlmm 82 GPIO_ACTIVE_HIGH>;

		vddaon-supply    = <&vreg_pmu_aon_0p59>;
		vddbtcmx-supply  = <&vreg_pmu_wlmx_0p85>;
		vddrfa0p8-supply = <&vreg_pmu_rfa_0p8>;
		vddrfa1p2-supply = <&vreg_pmu_rfa_1p2>;
		vddrfa1p8-supply = <&vreg_pmu_rfa_1p8>;
		vddrfacmn-supply = <&vreg_pmu_rfa_cmn>;
		vddwlcx-supply   = <&vreg_pmu_wlcx_0p8>;
		vddwlmx-supply   = <&vreg_pmu_wlmx_0p85>;

		max-speed = <3200000>;
	};
};

&tlmm {
	gpio-reserved-ranges = <36 4>;

	sde_dsi_active: sde-dsi-active-state {
		pins = "gpio133";
		function = "gpio";
		drive-strength = <8>;
		bias-disable;
	};

	sde_dsi_suspend: sde-dsi-suspend-state {
		pins = "gpio133";
		function = "gpio";
		drive-strength = <2>;
		bias-pull-down;
	};

	bt_default: bt-default-state {
		bt-en-pins {
			pins = "gpio81";
			function = "gpio";
			drive-strength = <16>;
			bias-disable;
		};
		sw-ctrl-pins {
			pins = "gpio82";
			function = "gpio";
			bias-pull-down;
		};
	};

	hall_sensor_default: hall-sensor-default-state {
		pins = "gpio107";
		function = "gpio";
		drive-strength = <2>;
		bias-pull-up;
	};

	wcd_default: wcd-reset-n-active-state {
		pins = "gpio108";
		function = "gpio";
		drive-strength = <16>;
		bias-disable;
		output-low;
	};

	i2s0_default: i2s0-default-state {
		sck-pins {
			pins = "gpio121";
			function = "i2s1_sck";
			drive-strength = <8>;
			bias-disable;
			output-high;
		};
		data0-pins {
			pins = "gpio122";
			function = "i2s1_data0";
			drive-strength = <8>;
			bias-disable;
		};
		ws-pins {
			pins = "gpio123";
			function = "i2s1_ws";
			drive-strength = <8>;
			bias-disable;
			output-high;
		};
		data1-pins {
			pins = "gpio124";
			function = "i2s1_data1";
			drive-strength = <8>;
			bias-disable;
			output-high;
		};
	};

	ps5169_reset_default: ps5169-reset-default-state {
		pins = "gpio7";
		function = "gpio";
		drive-strength = <2>;
		bias-pull-up;
	};

	wlan_en_active: wlan-en-active-state {
		pins = "gpio80";
		function = "gpio";
		drive-strength = <16>;
		bias-pull-up;
		output-high;
	};

	wlan_en_sleep: wlan-en-sleep-state {
		pins = "gpio80";
		function = "gpio";
		drive-strength = <2>;
		bias-pull-down;
		output-low;
	};

	bt_en_state: bt-en-state {
		pins = "gpio81";
		function = "gpio";
		drive-strength = <2>;
		bias-pull-down;
		output-low;
	};

	sw_ctrl: sw-ctrl-state {
		pins = "gpio82";
		function = "gpio";
		bias-pull-down;
		output-low;
	};

	xo_clk: xo-clk-state {
		pins = "gpio204";
		function = "gpio";
		bias-disable;
	};
};

&ufs_mem_hc {
	reset-gpios       = <&tlmm 210 GPIO_ACTIVE_LOW>;
	vcc-supply        = <&vreg_l17b_2p5>;
	vcc-max-microamp  = <1300000>;
	vccq-supply       = <&vreg_l1g_1p2>;
	vccq-max-microamp = <1200000>;
	vdd-hba-supply    = <&vreg_l3g_1p2>;
	status = "okay";
};

&ufs_mem_phy {
	vdda-phy-supply = <&vreg_l1d_0p88>;
	vdda-pll-supply = <&vreg_l3e_1p2>;
	status = "okay";
};

&usb_1 {
	status = "okay";
	dr_mode = "peripheral";
	maximum-speed = "high-speed";
	/delete-property/ usb-role-switch;
};

&usb_1_hsphy {
	vdd-supply    = <&vreg_l1e_0p88>;
	vdda12-supply = <&vreg_l3e_1p2>;
	phys = <&pm8550b_eusb2_repeater>;
	status = "okay";
};

&usb_dp_qmpphy {
	vdda-phy-supply = <&vreg_l3e_1p2>;
	vdda-pll-supply = <&vreg_l3f_0p91>;
	status = "okay";
};

&usb_dp_qmpphy_out { remote-endpoint = <&redriver_ss_in>; };

&sleep_clk { clock-frequency = <32764>; };
&xo_board   { clock-frequency = <76800000>; };

&soc {
	watchdog@17c10000 {
		compatible = "qcom,apss-wdt-sm8550", "qcom,kpss-wdt";
		reg = <0x0 0x17c10000 0x0 0x1000>;
		clocks = <&sleep_clk>;
		interrupts = <GIC_SPI 0 IRQ_TYPE_EDGE_RISING>;
	};
};
